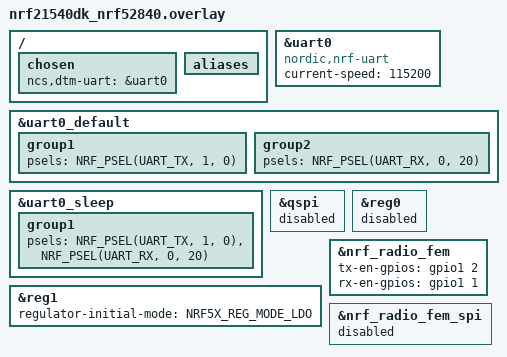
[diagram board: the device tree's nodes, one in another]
// To get started, press Ctrl+Space to bring up the completion menu and view the available nodes.

// You can also use the buttons in the sidebar to perform actions on nodes.
// Actions currently available include:

// * Enabling / disabling the node
// * Adding the bus to a bus
// * Removing the node
// * Connecting ADC channels

// For more help, browse the DeviceTree documentation at https://docs.zephyrproject.org/latest/guides/dts/index.html
// You can also visit the nRF DeviceTree extension documentation at https://docs.nordicsemi.com/bundle/nrf-connect-vscode/page/guides/ncs_configure_app.html#devicetree-support-in-the-extension

/* SPDX-License-Identifier: Apache-2.0 */
/ {
	chosen {
		ncs,dtm-uart = &uart0;
	};
};

&uart0 {
	compatible = "nordic,nrf-uart";
	current-speed = <115200>;
	status = "okay";
};

&uart0_default {
	group1 {
		psels = <NRF_PSEL(UART_TX, 1, 0)>;
		// psels = <NRF_PSEL(UART_TX, 1, 3)>, <NRF_PSEL(UART_RTS, 1, 4)>;
	};

	group2 {
		psels = <NRF_PSEL(UART_RX, 0, 20)>;
		// psels = <NRF_PSEL(UART_RX, 1, 5)>, <NRF_PSEL(UART_CTS, 1, 6)>;
	};
};

&uart0_sleep {
	group1 {
		psels = <NRF_PSEL(UART_TX, 1, 0)>, <NRF_PSEL(UART_RX, 0, 20)>;
		// psels = <NRF_PSEL(UART_TX, 1, 3)>, <NRF_PSEL(UART_RTS, 1, 4)>, <NRF_PSEL(UART_RX, 1, 5)>, <NRF_PSEL(UART_CTS, 1, 6)>;
	};
};

&qspi {
	status = "disabled";
};
/delete-node/ &button2;

/ {
	aliases {
		/delete-property/ sw2;
	};
};

&reg1 {
	regulator-initial-mode = <NRF5X_REG_MODE_LDO>;
    // regulator-initial-mode = <NRF5X_REG_MODE_DCDC>;
};
&reg0 {
    status = "disabled";
    // status = "okay";
};
&nrf_radio_fem {
	tx-en-gpios = <&gpio1 2 GPIO_ACTIVE_HIGH>;
	rx-en-gpios = <&gpio1 1 GPIO_ACTIVE_HIGH>;
	// pdn-gpios = <&gpio0 6 GPIO_ACTIVE_HIGH>; // Dummy
	/delete-property/ pdn-gpios;
	/delete-property/ spi-if;
	/delete-property/ mode-gpios;
	/delete-property/ ant-sel-gpios;
	// rx-en-settle-time-us = <11>;
};

&nrf_radio_fem_spi {
	status = "disabled";
};
